AUTOSAR XML (schema 314)
package /ComponentType
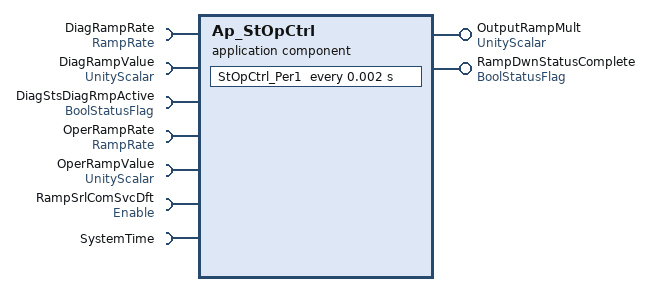
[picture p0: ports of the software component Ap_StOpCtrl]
  application software component type Ap_StOpCtrl
    provide port OutputRampMult: unqueued-sender-com-spec{data-element=Uls_f32, can-invalidate=false, init-value=D_ZERO_ULS_F32}, provided-interface=UnityScalar
    provide port RampDwnStatusComplete: unqueued-sender-com-spec{data-element=Cnt_lgc, can-invalidate=false, init-value=D_FALSE_CNT_LGC}, provided-interface=BoolStatusFlag
    7 x require port:
      DiagRampRate: unqueued-receiver-com-spec{data-element=XpmS_f32, init-value=D_ZERO_ULS_F32}, required-interface=RampRate
      DiagRampValue: unqueued-receiver-com-spec{data-element=Uls_f32, init-value=D_ZERO_ULS_F32}, required-interface=UnityScalar
      DiagStsDiagRmpActive: unqueued-receiver-com-spec{data-element=Cnt_lgc, init-value=D_FALSE_CNT_LGC}, required-interface=BoolStatusFlag
      OperRampRate: unqueued-receiver-com-spec{data-element=XpmS_f32, init-value=D_ZERO_ULS_F32}, required-interface=RampRate
      OperRampValue: unqueued-receiver-com-spec{data-element=Uls_f32, init-value=D_ZERO_ULS_F32}, required-interface=UnityScalar
      RampSrlComSvcDft: unqueued-receiver-com-spec{data-element=Cnt_lgc, init-value=D_FALSE_CNT_LGC}, required-interface=Enable
      SystemTime: required-interface=SystemTime
        required-com-specs:
          DtrmnElapsedTime_mS_u16
          DtrmnElapsedTime_mS_u32
          DtrmnElapsedTime_uS_u16
          DtrmnElapsedTime_uS_u32
          GetSystemTime_mS_u32
          GetSystemTime_uS_u32
  internal behavior Ap_StOpCtrl_InternalBehavior: component=Ap_StOpCtrl
    timing event TMT_StOpCtrl_Per1: start-on-event=StOpCtrl_Per1, period=0.002
    port-api-options:
      enable-take-address=false, indirect-api=false, port=DiagRampRate
      enable-take-address=false, indirect-api=false, port=DiagRampValue
      enable-take-address=false, indirect-api=false, port=DiagStsDiagRmpActive
      enable-take-address=false, indirect-api=false, port=OperRampRate
      enable-take-address=false, indirect-api=false, port=OperRampValue
      enable-take-address=false, indirect-api=false, port=OutputRampMult
      enable-take-address=false, indirect-api=false, port=RampDwnStatusComplete
      enable-take-address=false, indirect-api=false, port=RampSrlComSvcDft
      enable-take-address=false, indirect-api=false, port=SystemTime
    runnable StOpCtrl_Per1
      6 x data read access:
        READ_DiagRampRate_XpmS_f32: data-element=DiagRampRate.XpmS_f32
        READ_DiagRampValue_Uls_f32: data-element=DiagRampValue.Uls_f32
        READ_DiagStsDiagRmpActive_Cnt_lgc: data-element=DiagStsDiagRmpActive.Cnt_lgc
        READ_OperRampRate_XpmS_f32: data-element=OperRampRate.XpmS_f32
        READ_OperRampValue_Uls_f32: data-element=OperRampValue.Uls_f32
        READ_RampSrlComSvcDft_Cnt_lgc: data-element=RampSrlComSvcDft.Cnt_lgc
      data write access WRITE_OutputRampMult_Uls_f32: data-element=OutputRampMult.Uls_f32
      data write access WRITE_RampDwnStatusComplete_Cnt_lgc: data-element=RampDwnStatusComplete.Cnt_lgc
      sync call SC_SystemTime_DtrmnElapsedTime_mS_u32: operation=SystemTime.DtrmnElapsedTime_mS_u32, timeout=0
      sync call SC_SystemTime_GetSystemTime_mS_u32: operation=SystemTime.GetSystemTime_mS_u32, timeout=0
  swc implementation Ap_StOpCtrl_Implementation: behavior=Ap_StOpCtrl_InternalBehavior
    code-descriptors:
      code Code: type=SRC
